# STM32U5A9xx register map
File version: 1.0
Registers are 32-bit, read-write, reset 0x0 unless marked. A register's access mark holds for its fields unless they carry their own. Offsets are from the block's base; [hi:lo] are bit positions; {n}, {i} and the like mark numbered series; 'fields as' and 'values as' point back to an identical list.

## GTZC_TZSC1 — Global TrustZone Controller
Base 0x40032400
Same registers: GTZC_TZSC1_S 0x50032400
0x00 CR — TZSC control register
  [0] LCK
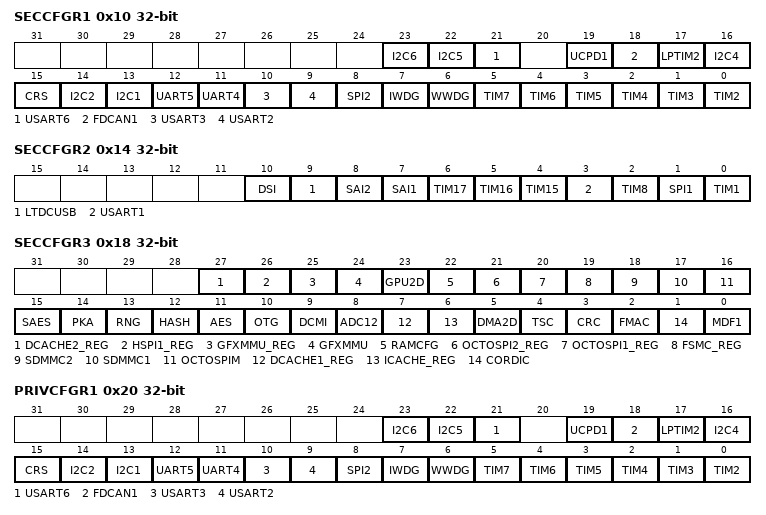
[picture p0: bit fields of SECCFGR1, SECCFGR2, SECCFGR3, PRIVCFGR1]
0x10 SECCFGR1 — TZSC secure configuration register 1
  [23] I2C6, [22] I2C5, [21] USART6, [19] UCPD1, [18] FDCAN1, [17] LPTIM2, [16] I2C4, [15] CRS, [14] I2C2, [13] I2C1, [12] UART5, [11] UART4, [10] USART3, [9] USART2, [8] SPI2, [7] IWDG, [6] WWDG, [n-2] TIM{n} (n=2..7)
0x14 SECCFGR2 — TZSC secure configuration register 2
  [10] DSI, [9] LTDCUSB, [8] SAI2, [7] SAI1, [6] TIM17, [5] TIM16, [4] TIM15, [3] USART1, [2] TIM8, [1] SPI1, [0] TIM1
0x18 SECCFGR3 — TZSC secure configuration register 3
  [27] DCACHE2_REG, [26] HSPI1_REG, [25] GFXMMU_REG, [24] GFXMMU, [23] GPU2D, [22] RAMCFG, [21] OCTOSPI2_REG, [20] OCTOSPI1_REG, [19] FSMC_REG, [18] SDMMC2, [17] SDMMC1, [16] OCTOSPIM, [15] SAES, [14] PKA, [13] RNG, [12] HASH, [11] AES, [10] OTG, [9] DCMI, [8] ADC12, [7] DCACHE1_REG, [6] ICACHE_REG, [5] DMA2D, [4] TSC, [3] CRC, [2] FMAC, [1] CORDIC, [0] MDF1
0x20 PRIVCFGR1 — TZSC privilege configuration register 1
  fields as SECCFGR1
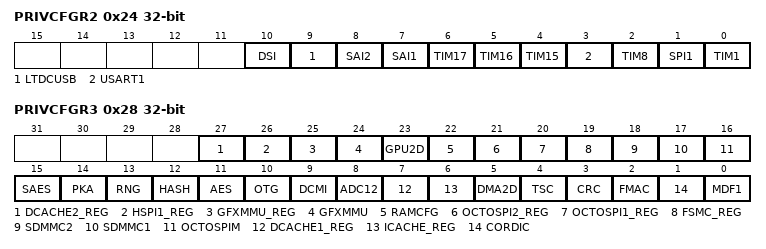
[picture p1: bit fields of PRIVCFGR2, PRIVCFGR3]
0x24 PRIVCFGR2 — TZSC privilege configuration register 2
  fields as SECCFGR2
0x28 PRIVCFGR3 — TZSC privilege configuration register 3
  fields as SECCFGR3
{0x30+0x10*i} MPCWM{i}ACFGR (i=1..6) — TZSC memory {i} sub-region A watermark configuration register
{0x34+0x10*i} MPCWM{i}AR (i=1..6) — TZSC memory {i} sub-region A watermark register
0x48 MPCWM1BCFGR — TZSC memory 1 sub-region B watermark configuration register
0x4C MPCWM1BR — TZSC memory 1 sub-region B watermark register
0x58 MPCWM2BCFGR — TZSC memory 2 sub-region B watermark configuration register
0x5C MPCWM2BR — TZSC memory 2 sub-region B watermark register
0x88 MPCWM5BCFGR — TZSC memory 5 sub-region B watermark configuration register
0x8C MPCWM5BR — TZSC memory 5 sub-region B watermark register
0x98 MPCWM6BCFGR — TZSC memory 6 sub-region B watermark configuration register
0x9C MPCWM6BR — TZSC memory 6 sub-region B watermark register

## GTZC_TZSC2 — Global TrustZone Controller
Base 0x46023000
Same registers: GTZC_TZSC2_S 0x56023000
Registers as GTZC_TZSC1; these are added or differ:
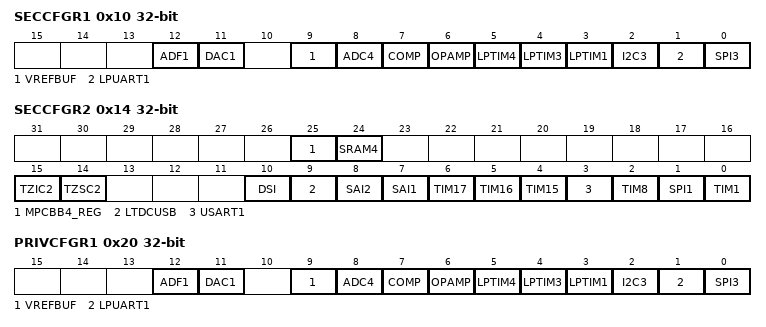
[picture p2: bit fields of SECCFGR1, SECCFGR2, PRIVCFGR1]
0x10 SECCFGR1 — TZSC secure configuration register 1
  [12] ADF1, [11] DAC1, [9] VREFBUF, [8] ADC4, [7] COMP, [6] OPAMP, [5] LPTIM4, [4] LPTIM3, [3] LPTIM1, [2] I2C3, [1] LPUART1, [0] SPI3
0x14 SECCFGR2 — TZSC secure configuration register 2
  [25] MPCBB4_REG, [24] SRAM4, [15] TZIC2, [14] TZSC2, [10] DSI, [9] LTDCUSB, [8] SAI2, [7] SAI1, [6] TIM17, [5] TIM16, [4] TIM15, [3] USART1, [2] TIM8, [1] SPI1, [0] TIM1
0x20 PRIVCFGR1 — TZSC privilege configuration register 1
  fields as SECCFGR1
0x24 PRIVCFGR2 — TZSC privilege configuration register 2
0x28 PRIVCFGR3 — TZSC privilege configuration register 3

## GTZC_TZIC1
Base 0x40032800
Same registers: GTZC_TZIC1_S 0x50032800
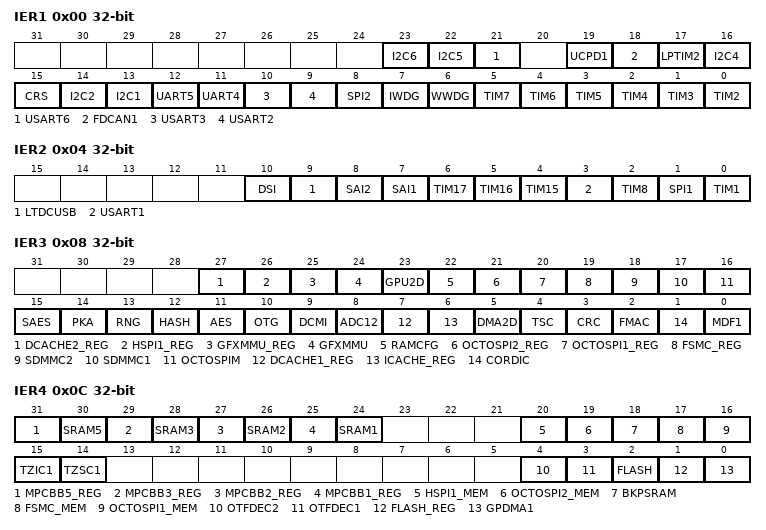
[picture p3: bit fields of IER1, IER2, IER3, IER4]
0x00 IER1 — TZIC interrupt enable register 1
  [23] I2C6, [22] I2C5, [21] USART6, [19] UCPD1, [18] FDCAN1, [17] LPTIM2, [16] I2C4, [15] CRS, [14] I2C2, [13] I2C1, [12] UART5, [11] UART4, [10] USART3, [9] USART2, [8] SPI2, [7] IWDG, [6] WWDG, [n-2] TIM{n} (n=2..7)
0x04 IER2 — TZIC interrupt enable register 2
  [10] DSI, [9] LTDCUSB, [8] SAI2, [7] SAI1, [6] TIM17, [5] TIM16, [4] TIM15, [3] USART1, [2] TIM8, [1] SPI1, [0] TIM1
0x08 IER3 — TZIC interrupt enable register 3
  [27] DCACHE2_REG, [26] HSPI1_REG, [25] GFXMMU_REG, [24] GFXMMU, [23] GPU2D, [22] RAMCFG, [21] OCTOSPI2_REG, [20] OCTOSPI1_REG, [19] FSMC_REG, [18] SDMMC2, [17] SDMMC1, [16] OCTOSPIM, [15] SAES, [14] PKA, [13] RNG, [12] HASH, [11] AES, [10] OTG, [9] DCMI, [8] ADC12, [7] DCACHE1_REG, [6] ICACHE_REG, [5] DMA2D, [4] TSC, [3] CRC, [2] FMAC, [1] CORDIC, [0] MDF1
0x0C IER4 — TZIC interrupt enable register 4
  [31] MPCBB5_REG, [30] SRAM5, [29] MPCBB3_REG, [28] SRAM3, [27] MPCBB2_REG, [26] SRAM2, [25] MPCBB1_REG, [24] SRAM1, [20] HSPI1_MEM, [19] OCTOSPI2_MEM, [18] BKPSRAM, [17] FSMC_MEM, [16] OCTOSPI1_MEM, [15] TZIC1, [14] TZSC1, [4] OTFDEC2, [3] OTFDEC1, [2] FLASH, [1] FLASH_REG, [0] GPDMA1
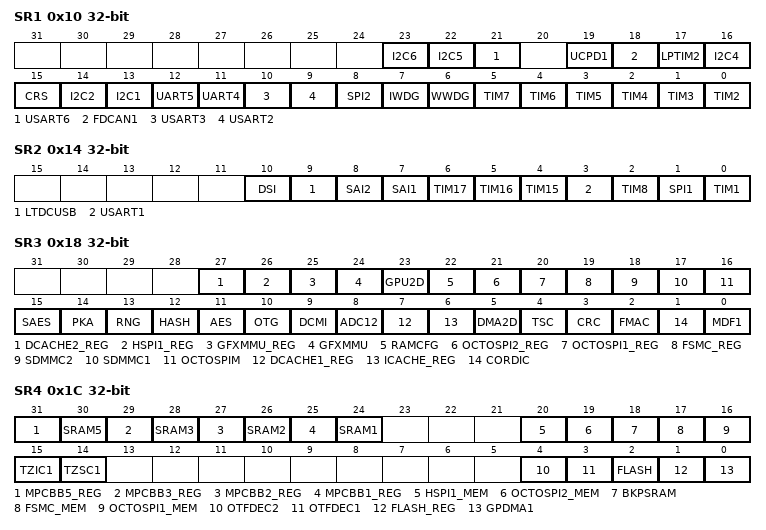
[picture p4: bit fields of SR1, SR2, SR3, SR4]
0x10 SR1 — TZIC status register 1
  fields as IER1
0x14 SR2 — TZIC status register 2
  fields as IER2
0x18 SR3 — TZIC status register 3
  fields as IER3
0x1C SR4 — TZIC status register 4
  fields as IER4
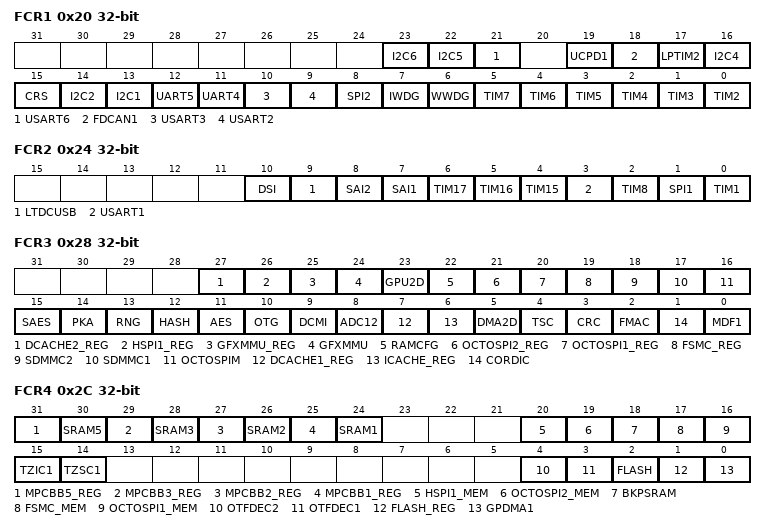
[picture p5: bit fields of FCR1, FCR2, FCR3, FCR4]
0x20 FCR1 — TZIC flag clear register 1
  fields as IER1
0x24 FCR2 — TZIC flag clear register 2
  fields as IER2
0x28 FCR3 — TZIC flag clear register 3
  fields as IER3
0x2C FCR4 — TZIC flag clear register 3
  fields as IER4
